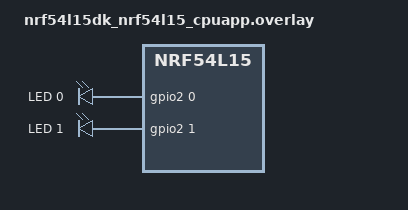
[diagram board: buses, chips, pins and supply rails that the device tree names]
/ {
	aliases {
		led0 = &led0;
		led1 = &led1;
	};

	leds {
		compatible = "gpio-leds";
		led0: led_0 {
			gpios = <&gpio2 0 GPIO_ACTIVE_HIGH>;
			label = "LED 0";
		};
		led1: led_1 {
			gpios = <&gpio2 1 GPIO_ACTIVE_HIGH>;
			label = "LED 1";
		};
	};
};
